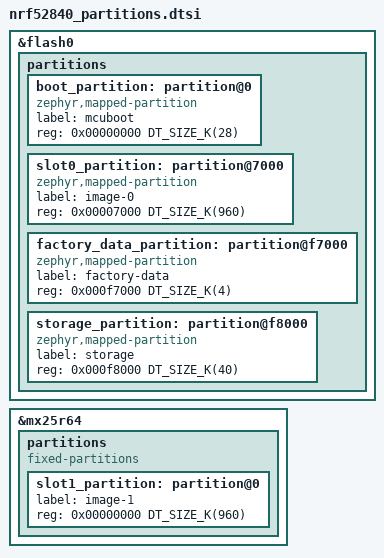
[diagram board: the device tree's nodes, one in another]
/*
 * Copyright (c) 2026 Nordic Semiconductor ASA
 *
 * SPDX-License-Identifier: LicenseRef-Nordic-5-Clause
 */

/delete-node/ &boot_partition;
/delete-node/ &slot0_partition;
/delete-node/ &slot1_partition;
/delete-node/ &storage_partition;

&flash0 {
	partitions {
		ranges;
		#address-cells = <1>;
		#size-cells = <1>;

		boot_partition: partition@0 {
			compatible = "zephyr,mapped-partition";
			label = "mcuboot";
			reg = <0x00000000 DT_SIZE_K(28)>;
		};

		slot0_partition: partition@7000 {
			compatible = "zephyr,mapped-partition";
			label = "image-0";
			reg = <0x00007000 DT_SIZE_K(960)>;
		};

		factory_data_partition: partition@f7000 {
			compatible = "zephyr,mapped-partition";
			label = "factory-data";
			reg = <0x000f7000 DT_SIZE_K(4)>;
		};

		storage_partition: partition@f8000 {
			compatible = "zephyr,mapped-partition";
			label = "storage";
			reg = <0x000f8000 DT_SIZE_K(40)>;
		};
	};
};

&mx25r64 {
	partitions {
		compatible = "fixed-partitions";
		#address-cells = <1>;
		#size-cells = <1>;

		slot1_partition: partition@0 {
			label = "image-1";
			reg = <0x00000000 DT_SIZE_K(960)>;
		};
	};
};
